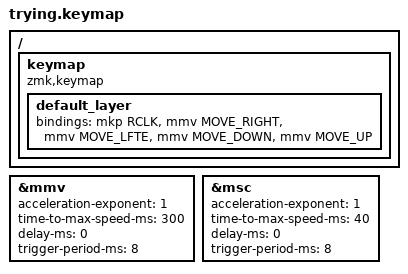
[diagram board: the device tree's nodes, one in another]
#include <behaviors.dtsi>
#include <dt-bindings/zmk/keys.h>
#include <dt-bindings/zmk/mouse.h>

&mmv {
    acceleration-exponent = <1>;      // 1
    time-to-max-speed-ms = <300>;     // 300
    delay-ms = <0>;                   // 0
    trigger-period-ms = <8>;          // 16
};

&msc {
    acceleration-exponent = <1>;      // 0
    time-to-max-speed-ms = <40>;      // 300
    delay-ms = <0>;                   // 0
    trigger-period-ms = <8>;          // 16
};

/{
 keymap {
        compatible = "zmk,keymap";

        default_layer {
            bindings = <
&mkp RCLK  &mmv MOVE_RIGHT  &mmv MOVE_LFTE &mmv MOVE_DOWN &mmv MOVE_UP
            >;
        };
    };
};
